# MSS_CTRL_MSS_CTRL_50D00000h register map
Vendor: Texas Instruments
Peripheral module from a debugger description file (folder AM261x).
Registers are 32-bit, read-write, reset values left out (the file's numbers can be read two ways) unless marked. A register's access mark holds for its fields unless they carry their own. Offsets are as the file gives them; lines under a group give offsets from that group; [hi:lo] are bit positions; {n}, {i} and the like mark numbered series; 'fields as' and 'values as' point back to an identical list; <NAME> marks a mode.

## MSS_CTRL (part 1 of 4)
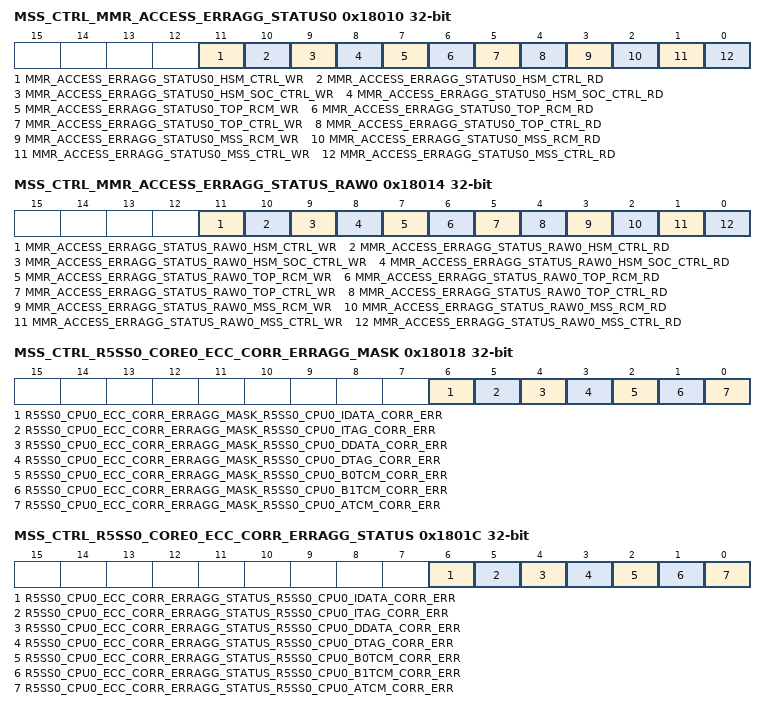
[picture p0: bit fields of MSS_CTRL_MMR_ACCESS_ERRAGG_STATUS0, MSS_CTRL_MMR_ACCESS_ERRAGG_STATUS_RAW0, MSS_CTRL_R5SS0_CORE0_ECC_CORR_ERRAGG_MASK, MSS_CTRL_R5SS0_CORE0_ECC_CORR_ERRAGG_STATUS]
0x18010 MSS_CTRL_MMR_ACCESS_ERRAGG_STATUS0 access not given — This register shows the Status of Unmasked MMR Access Errors.
  [11] MMR_ACCESS_ERRAGG_STATUS0_HSM_CTRL_WR — Status of Interrupt from HSM_CTRLSet only if Interupt is unmasked in MMR_ACCESS_ERRAGG_MASK0Wrie 0x1 to clear this interrupt. (access R/W1TC)
  [10] MMR_ACCESS_ERRAGG_STATUS0_HSM_CTRL_RD — Status of Interrupt from HSM_CTRLSet only if Interupt is unmasked in MMR_ACCESS_ERRAGG_MASK0Wrie 0x1 to clear this interrupt. (access R/W1TC)
  [9] MMR_ACCESS_ERRAGG_STATUS0_HSM_SOC_CTRL_WR — Status of Interrupt from HSM_SOC_CTRLSet only if Interupt is unmasked in MMR_ACCESS_ERRAGG_MASK0Wrie 0x1 to clear this interrupt. (access R/W1TC)
  [8] MMR_ACCESS_ERRAGG_STATUS0_HSM_SOC_CTRL_RD — Status of Interrupt from HSM_SOC_CTRLSet only if Interupt is unmasked in MMR_ACCESS_ERRAGG_MASK0Wrie 0x1 to clear this interrupt. (access R/W1TC)
  [7] MMR_ACCESS_ERRAGG_STATUS0_TOP_RCM_WR — Status of Interrupt from TOP_RCMSet only if Interupt is unmasked in MMR_ACCESS_ERRAGG_MASK0Wrie 0x1 to clear this interrupt. (access R/W1TC)
  [6] MMR_ACCESS_ERRAGG_STATUS0_TOP_RCM_RD — Status of Interrupt from TOP_RCMSet only if Interupt is unmasked in MMR_ACCESS_ERRAGG_MASK0Wrie 0x1 to clear this interrupt. (access R/W1TC)
  [5] MMR_ACCESS_ERRAGG_STATUS0_TOP_CTRL_WR — Status of Interrupt from TOP_CTRLSet only if Interupt is unmasked in MMR_ACCESS_ERRAGG_MASK0Wrie 0x1 to clear this interrupt. (access R/W1TC)
  [4] MMR_ACCESS_ERRAGG_STATUS0_TOP_CTRL_RD — Status of Interrupt from TOP_CTRLSet only if Interupt is unmasked in MMR_ACCESS_ERRAGG_MASK0Wrie 0x1 to clear this interrupt. (access R/W1TC)
  [3] MMR_ACCESS_ERRAGG_STATUS0_MSS_RCM_WR — Status of Interrupt from MSS_RCMSet only if Interupt is unmasked in MMR_ACCESS_ERRAGG_MASK0Wrie 0x1 to clear this interrupt. (access R/W1TC)
  [2] MMR_ACCESS_ERRAGG_STATUS0_MSS_RCM_RD — Status of Interrupt from MSS_RCMSet only if Interupt is unmasked in MMR_ACCESS_ERRAGG_MASK0Wrie 0x1 to clear this interrupt. (access R/W1TC)
  [1] MMR_ACCESS_ERRAGG_STATUS0_MSS_CTRL_WR — Status of Interrupt from MSS_CTRLSet only if Interupt is unmasked in MMR_ACCESS_ERRAGG_MASK0Wrie 0x1 to clear this interrupt. (access R/W1TC)
  [0] MMR_ACCESS_ERRAGG_STATUS0_MSS_CTRL_RD — Status of Interrupt from MSS_CTRLSet only if Interupt is unmasked in MMR_ACCESS_ERRAGG_MASK0Wrie 0x1 to clear this interrupt. (access R/W1TC)
0x18014 MSS_CTRL_MMR_ACCESS_ERRAGG_STATUS_RAW0 access not given — This register shows the Status of all MMR Access Errors.
  [11] MMR_ACCESS_ERRAGG_STATUS_RAW0_HSM_CTRL_WR — Raw Status of Interrupt from HSM_CTRL. Set irrespective if the Interupt is masked or unmasked in MMR_ACCESS_ERRAGG_MASK0 (access R/W1TC)
  [10] MMR_ACCESS_ERRAGG_STATUS_RAW0_HSM_CTRL_RD — Raw Status of Interrupt from HSM_CTRL. Set irrespective if the Interupt is masked or unmasked in MMR_ACCESS_ERRAGG_MASK0 (access R/W1TC)
  [9] MMR_ACCESS_ERRAGG_STATUS_RAW0_HSM_SOC_CTRL_WR — Raw Status of Interrupt from HSM_SOC_CTRL. Set irrespective if the Interupt is masked or unmasked in MMR_ACCESS_ERRAGG_MASK0 (access R/W1TC)
  [8] MMR_ACCESS_ERRAGG_STATUS_RAW0_HSM_SOC_CTRL_RD — Raw Status of Interrupt from HSM_SOC_CTRL. Set irrespective if the Interupt is masked or unmasked in MMR_ACCESS_ERRAGG_MASK0 (access R/W1TC)
  [7] MMR_ACCESS_ERRAGG_STATUS_RAW0_TOP_RCM_WR — Raw Status of Interrupt from TOP_RCM. Set irrespective if the Interupt is masked or unmasked in MMR_ACCESS_ERRAGG_MASK0 (access R/W1TC)
  [6] MMR_ACCESS_ERRAGG_STATUS_RAW0_TOP_RCM_RD — Raw Status of Interrupt from TOP_RCM. Set irrespective if the Interupt is masked or unmasked in MMR_ACCESS_ERRAGG_MASK0 (access R/W1TC)
  [5] MMR_ACCESS_ERRAGG_STATUS_RAW0_TOP_CTRL_WR — Raw Status of Interrupt from TOP_CTRL. Set irrespective if the Interupt is masked or unmasked in MMR_ACCESS_ERRAGG_MASK0 (access R/W1TC)
  [4] MMR_ACCESS_ERRAGG_STATUS_RAW0_TOP_CTRL_RD — Raw Status of Interrupt from TOP_CTRL. Set irrespective if the Interupt is masked or unmasked in MMR_ACCESS_ERRAGG_MASK0 (access R/W1TC)
  [3] MMR_ACCESS_ERRAGG_STATUS_RAW0_MSS_RCM_WR — Raw Status of Interrupt from MSS_RCM. Set irrespective if the Interupt is masked or unmasked in MMR_ACCESS_ERRAGG_MASK0 (access R/W1TC)
  [2] MMR_ACCESS_ERRAGG_STATUS_RAW0_MSS_RCM_RD — Raw Status of Interrupt from MSS_RCM. Set irrespective if the Interupt is masked or unmasked in MMR_ACCESS_ERRAGG_MASK0 (access R/W1TC)
  [1] MMR_ACCESS_ERRAGG_STATUS_RAW0_MSS_CTRL_WR — Raw Status of Interrupt from MSS_CTRL. Set irrespective if the Interupt is masked or unmasked in MMR_ACCESS_ERRAGG_MASK0 (access R/W1TC)
  [0] MMR_ACCESS_ERRAGG_STATUS_RAW0_MSS_CTRL_RD — Raw Status of Interrupt from MSS_CTRL. Set irrespective if the Interupt is masked or unmasked in MMR_ACCESS_ERRAGG_MASK0 (access R/W1TC)
0x18018 MSS_CTRL_R5SS0_CORE0_ECC_CORR_ERRAGG_MASK — Register to Mask Correctable error from R5SS0 CORE0 Memories.
  [6] R5SS0_CPU0_ECC_CORR_ERRAGG_MASK_R5SS0_CPU0_IDATA_CORR_ERR — Mask Interrupt for correctable errors to aggregated Interrupt of corresponding CPU1 : Interrupt is Masked0 : Interrupt is Unmasked
  [5] R5SS0_CPU0_ECC_CORR_ERRAGG_MASK_R5SS0_CPU0_ITAG_CORR_ERR — Mask Interrupt for correctable errors to aggregated Interrupt of corresponding CPU1 : Interrupt is Masked0 : Interrupt is Unmasked
  [4] R5SS0_CPU0_ECC_CORR_ERRAGG_MASK_R5SS0_CPU0_DDATA_CORR_ERR — Mask Interrupt for correctable errors to aggregated Interrupt of corresponding CPU1 : Interrupt is Masked0 : Interrupt is Unmasked
  [3] R5SS0_CPU0_ECC_CORR_ERRAGG_MASK_R5SS0_CPU0_DTAG_CORR_ERR — Mask Interrupt for correctable errors to aggregated Interrupt of corresponding CPU1 : Interrupt is Masked0 : Interrupt is Unmasked
  [2] R5SS0_CPU0_ECC_CORR_ERRAGG_MASK_R5SS0_CPU0_B0TCM_CORR_ERR — Mask Interrupt for correctable errors to aggregated Interrupt of corresponding CPU1 : Interrupt is Masked0 : Interrupt is Unmasked
  [1] R5SS0_CPU0_ECC_CORR_ERRAGG_MASK_R5SS0_CPU0_B1TCM_CORR_ERR — Mask Interrupt for correctable errors to aggregated Interrupt of corresponding CPU1 : Interrupt is Masked0 : Interrupt is Unmasked
  [0] R5SS0_CPU0_ECC_CORR_ERRAGG_MASK_R5SS0_CPU0_ATCM_CORR_ERR — Mask Interrupt for correctable errors to aggregated Interrupt of corresponding CPU1 : Interrupt is Masked0 : Interrupt is Unmasked
0x1801C MSS_CTRL_R5SS0_CORE0_ECC_CORR_ERRAGG_STATUS access not given — Status register based on mask for correctable error R5SS0 CORE0 Memories.
  [6] R5SS0_CPU0_ECC_CORR_ERRAGG_STATUS_R5SS0_CPU0_IDATA_CORR_ERR — Status of Interrupt from correctable error of corresponding CPUSet only if Interupt is unmasked in corresponding R5SS*_CPU*_ECC_CORR_ERRAGG_MASK registerWrie 0x1 to clear this interrupt. (access R/W1TC)
  [5] R5SS0_CPU0_ECC_CORR_ERRAGG_STATUS_R5SS0_CPU0_ITAG_CORR_ERR — Status of Interrupt from correctable error of corresponding CPUSet only if Interupt is unmasked in corresponding R5SS*_CPU*_ECC_CORR_ERRAGG_MASK registerWrie 0x1 to clear this interrupt. (access R/W1TC)
  [4] R5SS0_CPU0_ECC_CORR_ERRAGG_STATUS_R5SS0_CPU0_DDATA_CORR_ERR — Status of Interrupt from correctable error of corresponding CPUSet only if Interupt is unmasked in corresponding R5SS*_CPU*_ECC_CORR_ERRAGG_MASK registerWrie 0x1 to clear this interrupt. (access R/W1TC)
  [3] R5SS0_CPU0_ECC_CORR_ERRAGG_STATUS_R5SS0_CPU0_DTAG_CORR_ERR — Status of Interrupt from correctable error of corresponding CPUSet only if Interupt is unmasked in corresponding R5SS*_CPU*_ECC_CORR_ERRAGG_MASK registerWrie 0x1 to clear this interrupt. (access R/W1TC)
  [2] R5SS0_CPU0_ECC_CORR_ERRAGG_STATUS_R5SS0_CPU0_B0TCM_CORR_ERR — Status of Interrupt from correctable error of corresponding CPUSet only if Interupt is unmasked in corresponding R5SS*_CPU*_ECC_CORR_ERRAGG_MASK registerWrie 0x1 to clear this interrupt. (access R/W1TC)
  [1] R5SS0_CPU0_ECC_CORR_ERRAGG_STATUS_R5SS0_CPU0_B1TCM_CORR_ERR — Status of Interrupt from correctable error of corresponding CPUSet only if Interupt is unmasked in corresponding R5SS*_CPU*_ECC_CORR_ERRAGG_MASK registerWrie 0x1 to clear this interrupt. (access R/W1TC)
  [0] R5SS0_CPU0_ECC_CORR_ERRAGG_STATUS_R5SS0_CPU0_ATCM_CORR_ERR — Status of Interrupt from correctable error of corresponding CPUSet only if Interupt is unmasked in corresponding R5SS*_CPU*_ECC_CORR_ERRAGG_MASK registerWrie 0x1 to clear this interrupt. (access R/W1TC)
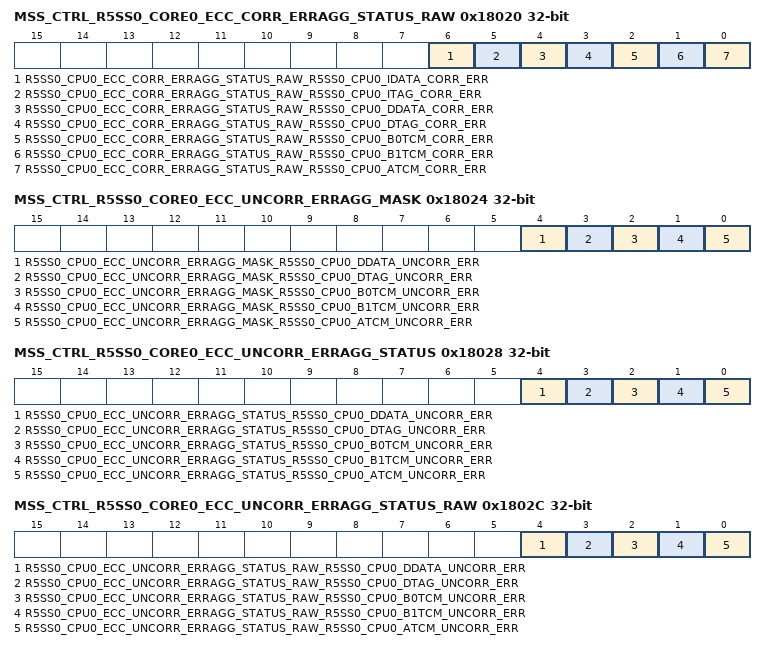
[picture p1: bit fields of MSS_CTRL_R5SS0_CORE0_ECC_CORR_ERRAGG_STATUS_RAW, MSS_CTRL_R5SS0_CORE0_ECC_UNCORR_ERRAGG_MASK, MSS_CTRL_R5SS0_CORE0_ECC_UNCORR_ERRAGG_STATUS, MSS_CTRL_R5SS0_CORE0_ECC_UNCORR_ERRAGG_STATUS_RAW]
0x18020 MSS_CTRL_R5SS0_CORE0_ECC_CORR_ERRAGG_STATUS_RAW access not given — Raw status for correctable error from R5SS0 CORE0 Memories.
  [6] R5SS0_CPU0_ECC_CORR_ERRAGG_STATUS_RAW_R5SS0_CPU0_IDATA_CORR_ERR — Raw Status of Interrupt from correctable error of corresponding CPUSet only if Interupt is unmasked in corresponding R5SS*_CPU*_ECC_CORR_ERRAGG_MASK registerWrie 0x1 to clear this interrupt. (access R/W1TC)
  [5] R5SS0_CPU0_ECC_CORR_ERRAGG_STATUS_RAW_R5SS0_CPU0_ITAG_CORR_ERR — Raw Status of Interrupt from correctable error of corresponding CPUSet only if Interupt is unmasked in corresponding R5SS*_CPU*_ECC_CORR_ERRAGG_MASK registerWrie 0x1 to clear this interrupt. (access R/W1TC)
  [4] R5SS0_CPU0_ECC_CORR_ERRAGG_STATUS_RAW_R5SS0_CPU0_DDATA_CORR_ERR — Raw Status of Interrupt from correctable error of corresponding CPUSet only if Interupt is unmasked in corresponding R5SS*_CPU*_ECC_CORR_ERRAGG_MASK registerWrie 0x1 to clear this interrupt. (access R/W1TC)
  [3] R5SS0_CPU0_ECC_CORR_ERRAGG_STATUS_RAW_R5SS0_CPU0_DTAG_CORR_ERR — Raw Status of Interrupt from correctable error of corresponding CPUSet only if Interupt is unmasked in corresponding R5SS*_CPU*_ECC_CORR_ERRAGG_MASK registerWrie 0x1 to clear this interrupt. (access R/W1TC)
  [2] R5SS0_CPU0_ECC_CORR_ERRAGG_STATUS_RAW_R5SS0_CPU0_B0TCM_CORR_ERR — Raw Status of Interrupt from correctable error of corresponding CPUSet only if Interupt is unmasked in corresponding R5SS*_CPU*_ECC_CORR_ERRAGG_MASK registerWrie 0x1 to clear this interrupt. (access R/W1TC)
  [1] R5SS0_CPU0_ECC_CORR_ERRAGG_STATUS_RAW_R5SS0_CPU0_B1TCM_CORR_ERR — Raw Status of Interrupt from correctable error of corresponding CPUSet only if Interupt is unmasked in corresponding R5SS*_CPU*_ECC_CORR_ERRAGG_MASK registerWrie 0x1 to clear this interrupt. (access R/W1TC)
  [0] R5SS0_CPU0_ECC_CORR_ERRAGG_STATUS_RAW_R5SS0_CPU0_ATCM_CORR_ERR — Raw Status of Interrupt from correctable error of corresponding CPUSet only if Interupt is unmasked in corresponding R5SS*_CPU*_ECC_CORR_ERRAGG_MASK registerWrie 0x1 to clear this interrupt. (access R/W1TC)
0x18024 MSS_CTRL_R5SS0_CORE0_ECC_UNCORR_ERRAGG_MASK — Register to Mask Uncorrectable error from R5SS0 CORE0 Memories.
  [4] R5SS0_CPU0_ECC_UNCORR_ERRAGG_MASK_R5SS0_CPU0_DDATA_UNCORR_ERR — Mask Interrupt for correctable errors to aggregated Interrupt of corresponding CPU1 : Interrupt is Masked0 : Interrupt is Unmasked
  [3] R5SS0_CPU0_ECC_UNCORR_ERRAGG_MASK_R5SS0_CPU0_DTAG_UNCORR_ERR — Mask Interrupt for correctable errors to aggregated Interrupt of corresponding CPU1 : Interrupt is Masked0 : Interrupt is Unmasked
  [2] R5SS0_CPU0_ECC_UNCORR_ERRAGG_MASK_R5SS0_CPU0_B0TCM_UNCORR_ERR — Mask Interrupt for correctable errors to aggregated Interrupt of corresponding CPU1 : Interrupt is Masked0 : Interrupt is Unmasked
  [1] R5SS0_CPU0_ECC_UNCORR_ERRAGG_MASK_R5SS0_CPU0_B1TCM_UNCORR_ERR — Mask Interrupt for correctable errors to aggregated Interrupt of corresponding CPU1 : Interrupt is Masked0 : Interrupt is Unmasked
  [0] R5SS0_CPU0_ECC_UNCORR_ERRAGG_MASK_R5SS0_CPU0_ATCM_UNCORR_ERR — Mask Interrupt for correctable errors to aggregated Interrupt of corresponding CPU1 : Interrupt is Masked0 : Interrupt is Unmasked
0x18028 MSS_CTRL_R5SS0_CORE0_ECC_UNCORR_ERRAGG_STATUS access not given — Status register based on mask for uncorrectable error R5SS0 CORE0 Memories.
  [4] R5SS0_CPU0_ECC_UNCORR_ERRAGG_STATUS_R5SS0_CPU0_DDATA_UNCORR_ERR — Status of Interrupt from correctable error of corresponding CPUSet only if Interupt is unmasked in corresponding R5SS*_CPU*_ECC_UNCORR_ERRAGG_MASK registerWrie 0x1 to clear this interrupt. (access R/W1TC)
  [3] R5SS0_CPU0_ECC_UNCORR_ERRAGG_STATUS_R5SS0_CPU0_DTAG_UNCORR_ERR — Status of Interrupt from correctable error of corresponding CPUSet only if Interupt is unmasked in corresponding R5SS*_CPU*_ECC_UNCORR_ERRAGG_MASK registerWrie 0x1 to clear this interrupt. (access R/W1TC)
  [2] R5SS0_CPU0_ECC_UNCORR_ERRAGG_STATUS_R5SS0_CPU0_B0TCM_UNCORR_ERR — Status of Interrupt from correctable error of corresponding CPUSet only if Interupt is unmasked in corresponding R5SS*_CPU*_ECC_UNCORR_ERRAGG_MASK registerWrie 0x1 to clear this interrupt. (access R/W1TC)
  [1] R5SS0_CPU0_ECC_UNCORR_ERRAGG_STATUS_R5SS0_CPU0_B1TCM_UNCORR_ERR — Status of Interrupt from correctable error of corresponding CPUSet only if Interupt is unmasked in corresponding R5SS*_CPU*_ECC_UNCORR_ERRAGG_MASK registerWrie 0x1 to clear this interrupt. (access R/W1TC)
  [0] R5SS0_CPU0_ECC_UNCORR_ERRAGG_STATUS_R5SS0_CPU0_ATCM_UNCORR_ERR — Status of Interrupt from correctable error of corresponding CPUSet only if Interupt is unmasked in corresponding R5SS*_CPU*_ECC_UNCORR_ERRAGG_MASK registerWrie 0x1 to clear this interrupt. (access R/W1TC)
0x1802C MSS_CTRL_R5SS0_CORE0_ECC_UNCORR_ERRAGG_STATUS_RAW access not given — Raw status for uncorrectable error from R5SS0 CORE0 Memories.
  [4] R5SS0_CPU0_ECC_UNCORR_ERRAGG_STATUS_RAW_R5SS0_CPU0_DDATA_UNCORR_ERR — Raw Status of Interrupt from correctable error of corresponding CPUSet only if Interupt is unmasked in corresponding R5SS*_CPU*_ECC_UNCORR_ERRAGG_MASK registerWrie 0x1 to clear this interrupt. (access R/W1TC)
  [3] R5SS0_CPU0_ECC_UNCORR_ERRAGG_STATUS_RAW_R5SS0_CPU0_DTAG_UNCORR_ERR — Raw Status of Interrupt from correctable error of corresponding CPUSet only if Interupt is unmasked in corresponding R5SS*_CPU*_ECC_UNCORR_ERRAGG_MASK registerWrie 0x1 to clear this interrupt. (access R/W1TC)
  [2] R5SS0_CPU0_ECC_UNCORR_ERRAGG_STATUS_RAW_R5SS0_CPU0_B0TCM_UNCORR_ERR — Raw Status of Interrupt from correctable error of corresponding CPUSet only if Interupt is unmasked in corresponding R5SS*_CPU*_ECC_UNCORR_ERRAGG_MASK registerWrie 0x1 to clear this interrupt. (access R/W1TC)
  [1] R5SS0_CPU0_ECC_UNCORR_ERRAGG_STATUS_RAW_R5SS0_CPU0_B1TCM_UNCORR_ERR — Raw Status of Interrupt from correctable error of corresponding CPUSet only if Interupt is unmasked in corresponding R5SS*_CPU*_ECC_UNCORR_ERRAGG_MASK registerWrie 0x1 to clear this interrupt. (access R/W1TC)
  [0] R5SS0_CPU0_ECC_UNCORR_ERRAGG_STATUS_RAW_R5SS0_CPU0_ATCM_UNCORR_ERR — Raw Status of Interrupt from correctable error of corresponding CPUSet only if Interupt is unmasked in corresponding R5SS*_CPU*_ECC_UNCORR_ERRAGG_MASK registerWrie 0x1 to clear this interrupt. (access R/W1TC)
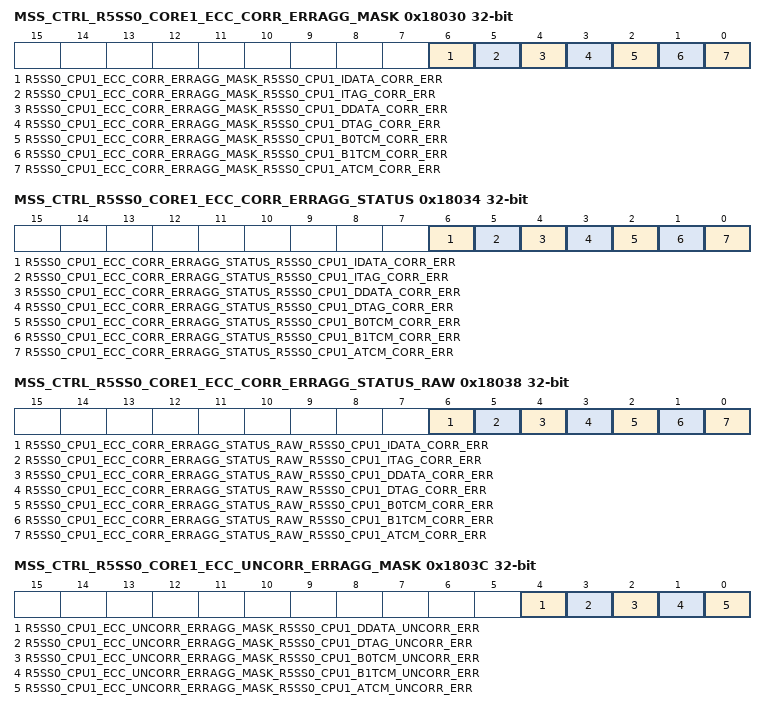
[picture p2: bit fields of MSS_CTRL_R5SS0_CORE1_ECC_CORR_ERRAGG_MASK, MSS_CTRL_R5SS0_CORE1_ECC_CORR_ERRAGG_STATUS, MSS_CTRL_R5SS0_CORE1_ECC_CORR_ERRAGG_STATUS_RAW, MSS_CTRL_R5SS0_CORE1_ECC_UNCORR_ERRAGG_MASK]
0x18030 MSS_CTRL_R5SS0_CORE1_ECC_CORR_ERRAGG_MASK — Register to Mask Correctable error from R5SS0 CORE1 Memories.
  [6] R5SS0_CPU1_ECC_CORR_ERRAGG_MASK_R5SS0_CPU1_IDATA_CORR_ERR — Mask Interrupt for correctable errors to aggregated Interrupt of corresponding CPU1 : Interrupt is Masked0 : Interrupt is Unmasked
  [5] R5SS0_CPU1_ECC_CORR_ERRAGG_MASK_R5SS0_CPU1_ITAG_CORR_ERR — Mask Interrupt for correctable errors to aggregated Interrupt of corresponding CPU1 : Interrupt is Masked0 : Interrupt is Unmasked
  [4] R5SS0_CPU1_ECC_CORR_ERRAGG_MASK_R5SS0_CPU1_DDATA_CORR_ERR — Mask Interrupt for correctable errors to aggregated Interrupt of corresponding CPU1 : Interrupt is Masked0 : Interrupt is Unmasked
  [3] R5SS0_CPU1_ECC_CORR_ERRAGG_MASK_R5SS0_CPU1_DTAG_CORR_ERR — Mask Interrupt for correctable errors to aggregated Interrupt of corresponding CPU1 : Interrupt is Masked0 : Interrupt is Unmasked
  [2] R5SS0_CPU1_ECC_CORR_ERRAGG_MASK_R5SS0_CPU1_B0TCM_CORR_ERR — Mask Interrupt for correctable errors to aggregated Interrupt of corresponding CPU1 : Interrupt is Masked0 : Interrupt is Unmasked
  [1] R5SS0_CPU1_ECC_CORR_ERRAGG_MASK_R5SS0_CPU1_B1TCM_CORR_ERR — Mask Interrupt for correctable errors to aggregated Interrupt of corresponding CPU1 : Interrupt is Masked0 : Interrupt is Unmasked
  [0] R5SS0_CPU1_ECC_CORR_ERRAGG_MASK_R5SS0_CPU1_ATCM_CORR_ERR — Mask Interrupt for correctable errors to aggregated Interrupt of corresponding CPU1 : Interrupt is Masked0 : Interrupt is Unmasked
0x18034 MSS_CTRL_R5SS0_CORE1_ECC_CORR_ERRAGG_STATUS access not given — Status register based on mask for correctable error R5SS0 CORE1 Memories.
  [6] R5SS0_CPU1_ECC_CORR_ERRAGG_STATUS_R5SS0_CPU1_IDATA_CORR_ERR — Status of Interrupt from correctable error of corresponding CPUSet only if Interupt is unmasked in corresponding R5SS*_CPU*_ECC_CORR_ERRAGG_MASK registerWrie 0x1 to clear this interrupt. (access R/W1TC)
  [5] R5SS0_CPU1_ECC_CORR_ERRAGG_STATUS_R5SS0_CPU1_ITAG_CORR_ERR — Status of Interrupt from correctable error of corresponding CPUSet only if Interupt is unmasked in corresponding R5SS*_CPU*_ECC_CORR_ERRAGG_MASK registerWrie 0x1 to clear this interrupt. (access R/W1TC)
  [4] R5SS0_CPU1_ECC_CORR_ERRAGG_STATUS_R5SS0_CPU1_DDATA_CORR_ERR — Status of Interrupt from correctable error of corresponding CPUSet only if Interupt is unmasked in corresponding R5SS*_CPU*_ECC_CORR_ERRAGG_MASK registerWrie 0x1 to clear this interrupt. (access R/W1TC)
  [3] R5SS0_CPU1_ECC_CORR_ERRAGG_STATUS_R5SS0_CPU1_DTAG_CORR_ERR — Status of Interrupt from correctable error of corresponding CPUSet only if Interupt is unmasked in corresponding R5SS*_CPU*_ECC_CORR_ERRAGG_MASK registerWrie 0x1 to clear this interrupt. (access R/W1TC)
  [2] R5SS0_CPU1_ECC_CORR_ERRAGG_STATUS_R5SS0_CPU1_B0TCM_CORR_ERR — Status of Interrupt from correctable error of corresponding CPUSet only if Interupt is unmasked in corresponding R5SS*_CPU*_ECC_CORR_ERRAGG_MASK registerWrie 0x1 to clear this interrupt. (access R/W1TC)
  [1] R5SS0_CPU1_ECC_CORR_ERRAGG_STATUS_R5SS0_CPU1_B1TCM_CORR_ERR — Status of Interrupt from correctable error of corresponding CPUSet only if Interupt is unmasked in corresponding R5SS*_CPU*_ECC_CORR_ERRAGG_MASK registerWrie 0x1 to clear this interrupt. (access R/W1TC)
  [0] R5SS0_CPU1_ECC_CORR_ERRAGG_STATUS_R5SS0_CPU1_ATCM_CORR_ERR — Status of Interrupt from correctable error of corresponding CPUSet only if Interupt is unmasked in corresponding R5SS*_CPU*_ECC_CORR_ERRAGG_MASK registerWrie 0x1 to clear this interrupt. (access R/W1TC)
0x18038 MSS_CTRL_R5SS0_CORE1_ECC_CORR_ERRAGG_STATUS_RAW access not given — Raw status for correctable error from R5SS0 CORE1 Memories.
  [6] R5SS0_CPU1_ECC_CORR_ERRAGG_STATUS_RAW_R5SS0_CPU1_IDATA_CORR_ERR — Raw Status of Interrupt from correctable error of corresponding CPUSet only if Interupt is unmasked in corresponding R5SS*_CPU*_ECC_CORR_ERRAGG_MASK registerWrie 0x1 to clear this interrupt. (access R/W1TC)
  [5] R5SS0_CPU1_ECC_CORR_ERRAGG_STATUS_RAW_R5SS0_CPU1_ITAG_CORR_ERR — Raw Status of Interrupt from correctable error of corresponding CPUSet only if Interupt is unmasked in corresponding R5SS*_CPU*_ECC_CORR_ERRAGG_MASK registerWrie 0x1 to clear this interrupt. (access R/W1TC)
  [4] R5SS0_CPU1_ECC_CORR_ERRAGG_STATUS_RAW_R5SS0_CPU1_DDATA_CORR_ERR — Raw Status of Interrupt from correctable error of corresponding CPUSet only if Interupt is unmasked in corresponding R5SS*_CPU*_ECC_CORR_ERRAGG_MASK registerWrie 0x1 to clear this interrupt. (access R/W1TC)
  [3] R5SS0_CPU1_ECC_CORR_ERRAGG_STATUS_RAW_R5SS0_CPU1_DTAG_CORR_ERR — Raw Status of Interrupt from correctable error of corresponding CPUSet only if Interupt is unmasked in corresponding R5SS*_CPU*_ECC_CORR_ERRAGG_MASK registerWrie 0x1 to clear this interrupt. (access R/W1TC)
  [2] R5SS0_CPU1_ECC_CORR_ERRAGG_STATUS_RAW_R5SS0_CPU1_B0TCM_CORR_ERR — Raw Status of Interrupt from correctable error of corresponding CPUSet only if Interupt is unmasked in corresponding R5SS*_CPU*_ECC_CORR_ERRAGG_MASK registerWrie 0x1 to clear this interrupt. (access R/W1TC)
  [1] R5SS0_CPU1_ECC_CORR_ERRAGG_STATUS_RAW_R5SS0_CPU1_B1TCM_CORR_ERR — Raw Status of Interrupt from correctable error of corresponding CPUSet only if Interupt is unmasked in corresponding R5SS*_CPU*_ECC_CORR_ERRAGG_MASK registerWrie 0x1 to clear this interrupt. (access R/W1TC)
  [0] R5SS0_CPU1_ECC_CORR_ERRAGG_STATUS_RAW_R5SS0_CPU1_ATCM_CORR_ERR — Raw Status of Interrupt from correctable error of corresponding CPUSet only if Interupt is unmasked in corresponding R5SS*_CPU*_ECC_CORR_ERRAGG_MASK registerWrie 0x1 to clear this interrupt. (access R/W1TC)
0x1803C MSS_CTRL_R5SS0_CORE1_ECC_UNCORR_ERRAGG_MASK — Register to Mask Uncorrectable error from R5SS0 CORE1 Memories.
  [4] R5SS0_CPU1_ECC_UNCORR_ERRAGG_MASK_R5SS0_CPU1_DDATA_UNCORR_ERR — Mask Interrupt for correctable errors to aggregated Interrupt of corresponding CPU1 : Interrupt is Masked0 : Interrupt is Unmasked
  [3] R5SS0_CPU1_ECC_UNCORR_ERRAGG_MASK_R5SS0_CPU1_DTAG_UNCORR_ERR — Mask Interrupt for correctable errors to aggregated Interrupt of corresponding CPU1 : Interrupt is Masked0 : Interrupt is Unmasked
  [2] R5SS0_CPU1_ECC_UNCORR_ERRAGG_MASK_R5SS0_CPU1_B0TCM_UNCORR_ERR — Mask Interrupt for correctable errors to aggregated Interrupt of corresponding CPU1 : Interrupt is Masked0 : Interrupt is Unmasked
  [1] R5SS0_CPU1_ECC_UNCORR_ERRAGG_MASK_R5SS0_CPU1_B1TCM_UNCORR_ERR — Mask Interrupt for correctable errors to aggregated Interrupt of corresponding CPU1 : Interrupt is Masked0 : Interrupt is Unmasked
  [0] R5SS0_CPU1_ECC_UNCORR_ERRAGG_MASK_R5SS0_CPU1_ATCM_UNCORR_ERR — Mask Interrupt for correctable errors to aggregated Interrupt of corresponding CPU1 : Interrupt is Masked0 : Interrupt is Unmasked
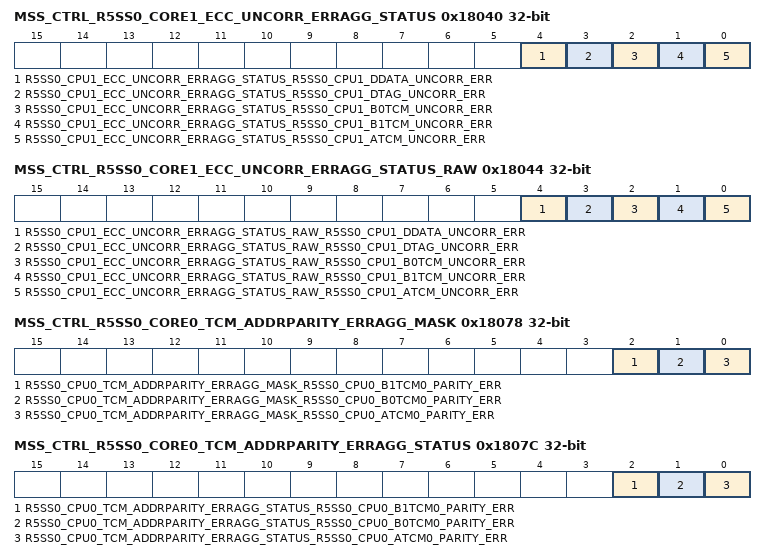
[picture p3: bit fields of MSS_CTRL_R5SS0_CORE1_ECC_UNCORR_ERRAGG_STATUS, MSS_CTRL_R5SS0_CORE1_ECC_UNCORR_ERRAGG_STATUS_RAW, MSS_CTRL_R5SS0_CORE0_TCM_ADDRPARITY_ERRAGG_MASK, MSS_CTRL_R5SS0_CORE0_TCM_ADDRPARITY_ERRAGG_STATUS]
0x18040 MSS_CTRL_R5SS0_CORE1_ECC_UNCORR_ERRAGG_STATUS access not given — Status register based on mask for uncorrectable error R5SS0 CORE1 Memories.
  [4] R5SS0_CPU1_ECC_UNCORR_ERRAGG_STATUS_R5SS0_CPU1_DDATA_UNCORR_ERR — Status of Interrupt from correctable error of corresponding CPUSet only if Interupt is unmasked in corresponding R5SS*_CPU*_ECC_UNCORR_ERRAGG_MASK registerWrie 0x1 to clear this interrupt. (access R/W1TC)
  [3] R5SS0_CPU1_ECC_UNCORR_ERRAGG_STATUS_R5SS0_CPU1_DTAG_UNCORR_ERR — Status of Interrupt from correctable error of corresponding CPUSet only if Interupt is unmasked in corresponding R5SS*_CPU*_ECC_UNCORR_ERRAGG_MASK registerWrie 0x1 to clear this interrupt. (access R/W1TC)
  [2] R5SS0_CPU1_ECC_UNCORR_ERRAGG_STATUS_R5SS0_CPU1_B0TCM_UNCORR_ERR — Status of Interrupt from correctable error of corresponding CPUSet only if Interupt is unmasked in corresponding R5SS*_CPU*_ECC_UNCORR_ERRAGG_MASK registerWrie 0x1 to clear this interrupt. (access R/W1TC)
  [1] R5SS0_CPU1_ECC_UNCORR_ERRAGG_STATUS_R5SS0_CPU1_B1TCM_UNCORR_ERR — Status of Interrupt from correctable error of corresponding CPUSet only if Interupt is unmasked in corresponding R5SS*_CPU*_ECC_UNCORR_ERRAGG_MASK registerWrie 0x1 to clear this interrupt. (access R/W1TC)
  [0] R5SS0_CPU1_ECC_UNCORR_ERRAGG_STATUS_R5SS0_CPU1_ATCM_UNCORR_ERR — Status of Interrupt from correctable error of corresponding CPUSet only if Interupt is unmasked in corresponding R5SS*_CPU*_ECC_UNCORR_ERRAGG_MASK registerWrie 0x1 to clear this interrupt. (access R/W1TC)
0x18044 MSS_CTRL_R5SS0_CORE1_ECC_UNCORR_ERRAGG_STATUS_RAW access not given — Raw status for uncorrectable error from R5SS0 CORE1 Memories.
  [4] R5SS0_CPU1_ECC_UNCORR_ERRAGG_STATUS_RAW_R5SS0_CPU1_DDATA_UNCORR_ERR — Raw Status of Interrupt from correctable error of corresponding CPUSet only if Interupt is unmasked in corresponding R5SS*_CPU*_ECC_UNCORR_ERRAGG_MASK registerWrie 0x1 to clear this interrupt. (access R/W1TC)
  [3] R5SS0_CPU1_ECC_UNCORR_ERRAGG_STATUS_RAW_R5SS0_CPU1_DTAG_UNCORR_ERR — Raw Status of Interrupt from correctable error of corresponding CPUSet only if Interupt is unmasked in corresponding R5SS*_CPU*_ECC_UNCORR_ERRAGG_MASK registerWrie 0x1 to clear this interrupt. (access R/W1TC)
  [2] R5SS0_CPU1_ECC_UNCORR_ERRAGG_STATUS_RAW_R5SS0_CPU1_B0TCM_UNCORR_ERR — Raw Status of Interrupt from correctable error of corresponding CPUSet only if Interupt is unmasked in corresponding R5SS*_CPU*_ECC_UNCORR_ERRAGG_MASK registerWrie 0x1 to clear this interrupt. (access R/W1TC)
  [1] R5SS0_CPU1_ECC_UNCORR_ERRAGG_STATUS_RAW_R5SS0_CPU1_B1TCM_UNCORR_ERR — Raw Status of Interrupt from correctable error of corresponding CPUSet only if Interupt is unmasked in corresponding R5SS*_CPU*_ECC_UNCORR_ERRAGG_MASK registerWrie 0x1 to clear this interrupt. (access R/W1TC)
  [0] R5SS0_CPU1_ECC_UNCORR_ERRAGG_STATUS_RAW_R5SS0_CPU1_ATCM_UNCORR_ERR — Raw Status of Interrupt from correctable error of corresponding CPUSet only if Interupt is unmasked in corresponding R5SS*_CPU*_ECC_UNCORR_ERRAGG_MASK registerWrie 0x1 to clear this interrupt. (access R/W1TC)
0x18078 MSS_CTRL_R5SS0_CORE0_TCM_ADDRPARITY_ERRAGG_MASK — Register to Mask TCM address parity errors from R5SS0 CORE0.
  [2] R5SS0_CPU0_TCM_ADDRPARITY_ERRAGG_MASK_R5SS0_CPU0_B1TCM0_PARITY_ERR — Mask Interrupt for address parity error s to aggregated Interrupt of corresponding CPU1 : Interrupt is Masked0 : Interrupt is Unmasked
  [1] R5SS0_CPU0_TCM_ADDRPARITY_ERRAGG_MASK_R5SS0_CPU0_B0TCM0_PARITY_ERR — Mask Interrupt for address parity error s to aggregated Interrupt of corresponding CPU1 : Interrupt is Masked0 : Interrupt is Unmasked
  [0] R5SS0_CPU0_TCM_ADDRPARITY_ERRAGG_MASK_R5SS0_CPU0_ATCM0_PARITY_ERR — Mask Interrupt for address parity error s to aggregated Interrupt of corresponding CPU1 : Interrupt is Masked0 : Interrupt is Unmasked
0x1807C MSS_CTRL_R5SS0_CORE0_TCM_ADDRPARITY_ERRAGG_STATUS access not given — Status register based on mask for TCM address parity errors from R5SS0 CORE0.
  [2] R5SS0_CPU0_TCM_ADDRPARITY_ERRAGG_STATUS_R5SS0_CPU0_B1TCM0_PARITY_ERR — Status of Interrupt from address parity error of corresponding CPU*_TCM_ADDRPARITY_ERRAGG_MASK registerWrie 0x1 to clear this interrupt. (access R/W1TC)
  [1] R5SS0_CPU0_TCM_ADDRPARITY_ERRAGG_STATUS_R5SS0_CPU0_B0TCM0_PARITY_ERR — Status of Interrupt from address parity error of corresponding CPU*_TCM_ADDRPARITY_ERRAGG_MASK registerWrie 0x1 to clear this interrupt. (access R/W1TC)
  [0] R5SS0_CPU0_TCM_ADDRPARITY_ERRAGG_STATUS_R5SS0_CPU0_ATCM0_PARITY_ERR — Status of Interrupt from address parity error of corresponding CPU*_TCM_ADDRPARITY_ERRAGG_MASK registerWrie 0x1 to clear this interrupt. (access R/W1TC)
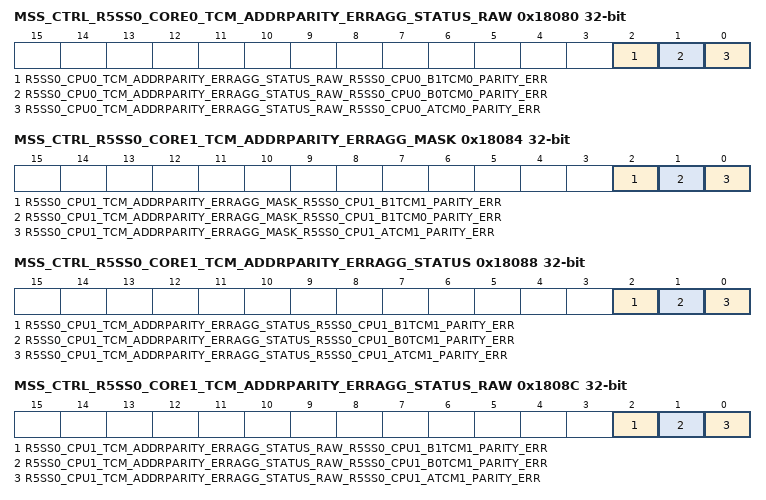
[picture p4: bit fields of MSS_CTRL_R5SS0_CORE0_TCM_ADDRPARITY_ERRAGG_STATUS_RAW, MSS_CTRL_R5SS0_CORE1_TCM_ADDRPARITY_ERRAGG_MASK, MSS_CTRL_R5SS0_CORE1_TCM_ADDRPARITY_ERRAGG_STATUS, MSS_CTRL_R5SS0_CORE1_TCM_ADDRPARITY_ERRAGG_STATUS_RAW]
0x18080 MSS_CTRL_R5SS0_CORE0_TCM_ADDRPARITY_ERRAGG_STATUS_RAW access not given — Raw status for TCM address parity errors from R5SS0 CORE0.
  [2] R5SS0_CPU0_TCM_ADDRPARITY_ERRAGG_STATUS_RAW_R5SS0_CPU0_B1TCM0_PARITY_ERR — Raw Status of Interrupt from address parity error of corresponding CPU*_TCM_ADDRPARITY_ERRAGG_MASK registerWrie 0x1 to clear this interrupt. (access R/W1TC)
  [1] R5SS0_CPU0_TCM_ADDRPARITY_ERRAGG_STATUS_RAW_R5SS0_CPU0_B0TCM0_PARITY_ERR — Raw Status of Interrupt from address parity error of corresponding CPU*_TCM_ADDRPARITY_ERRAGG_MASK registerWrie 0x1 to clear this interrupt. (access R/W1TC)
  [0] R5SS0_CPU0_TCM_ADDRPARITY_ERRAGG_STATUS_RAW_R5SS0_CPU0_ATCM0_PARITY_ERR — Raw Status of Interrupt from address parity error of corresponding CPU*_TCM_ADDRPARITY_ERRAGG_MASK registerWrie 0x1 to clear this interrupt. (access R/W1TC)
0x18084 MSS_CTRL_R5SS0_CORE1_TCM_ADDRPARITY_ERRAGG_MASK — Register to Mask TCM address parity errors from R5SS0 CORE1.
  [2] R5SS0_CPU1_TCM_ADDRPARITY_ERRAGG_MASK_R5SS0_CPU1_B1TCM1_PARITY_ERR — Mask Interrupt for address parity error s to aggregated Interrupt of corresponding CPU1 : Interrupt is Masked0 : Interrupt is Unmasked
  [1] R5SS0_CPU1_TCM_ADDRPARITY_ERRAGG_MASK_R5SS0_CPU1_B1TCM0_PARITY_ERR — Mask Interrupt for address parity error s to aggregated Interrupt of corresponding CPU1 : Interrupt is Masked0 : Interrupt is Unmasked
  [0] R5SS0_CPU1_TCM_ADDRPARITY_ERRAGG_MASK_R5SS0_CPU1_ATCM1_PARITY_ERR — Mask Interrupt for address parity error s to aggregated Interrupt of corresponding CPU1 : Interrupt is Masked0 : Interrupt is Unmasked
0x18088 MSS_CTRL_R5SS0_CORE1_TCM_ADDRPARITY_ERRAGG_STATUS access not given — Status register based on mask for TCM address parity errors from R5SS0 CORE1.
  [2] R5SS0_CPU1_TCM_ADDRPARITY_ERRAGG_STATUS_R5SS0_CPU1_B1TCM1_PARITY_ERR — Status of Interrupt from address parity error of corresponding CPU*_TCM_ADDRPARITY_ERRAGG_MASK registerWrie 0x1 to clear this interrupt. (access R/W1TC)
  [1] R5SS0_CPU1_TCM_ADDRPARITY_ERRAGG_STATUS_R5SS0_CPU1_B0TCM1_PARITY_ERR — Status of Interrupt from address parity error of corresponding CPU*_TCM_ADDRPARITY_ERRAGG_MASK registerWrie 0x1 to clear this interrupt. (access R/W1TC)
  [0] R5SS0_CPU1_TCM_ADDRPARITY_ERRAGG_STATUS_R5SS0_CPU1_ATCM1_PARITY_ERR — Status of Interrupt from address parity error of corresponding CPU*_TCM_ADDRPARITY_ERRAGG_MASK registerWrie 0x1 to clear this interrupt. (access R/W1TC)
0x1808C MSS_CTRL_R5SS0_CORE1_TCM_ADDRPARITY_ERRAGG_STATUS_RAW access not given — Raw status for TCM address parity errors from R5SS0 CORE1.
  [2] R5SS0_CPU1_TCM_ADDRPARITY_ERRAGG_STATUS_RAW_R5SS0_CPU1_B1TCM1_PARITY_ERR — Raw Status of Interrupt from address parity error of corresponding CPU*_TCM_ADDRPARITY_ERRAGG_MASK registerWrie 0x1 to clear this interrupt. (access R/W1TC)
  [1] R5SS0_CPU1_TCM_ADDRPARITY_ERRAGG_STATUS_RAW_R5SS0_CPU1_B0TCM1_PARITY_ERR — Raw Status of Interrupt from address parity error of corresponding CPU*_TCM_ADDRPARITY_ERRAGG_MASK registerWrie 0x1 to clear this interrupt. (access R/W1TC)
  [0] R5SS0_CPU1_TCM_ADDRPARITY_ERRAGG_STATUS_RAW_R5SS0_CPU1_ATCM1_PARITY_ERR — Raw Status of Interrupt from address parity error of corresponding CPU*_TCM_ADDRPARITY_ERRAGG_MASK registerWrie 0x1 to clear this interrupt. (access R/W1TC)
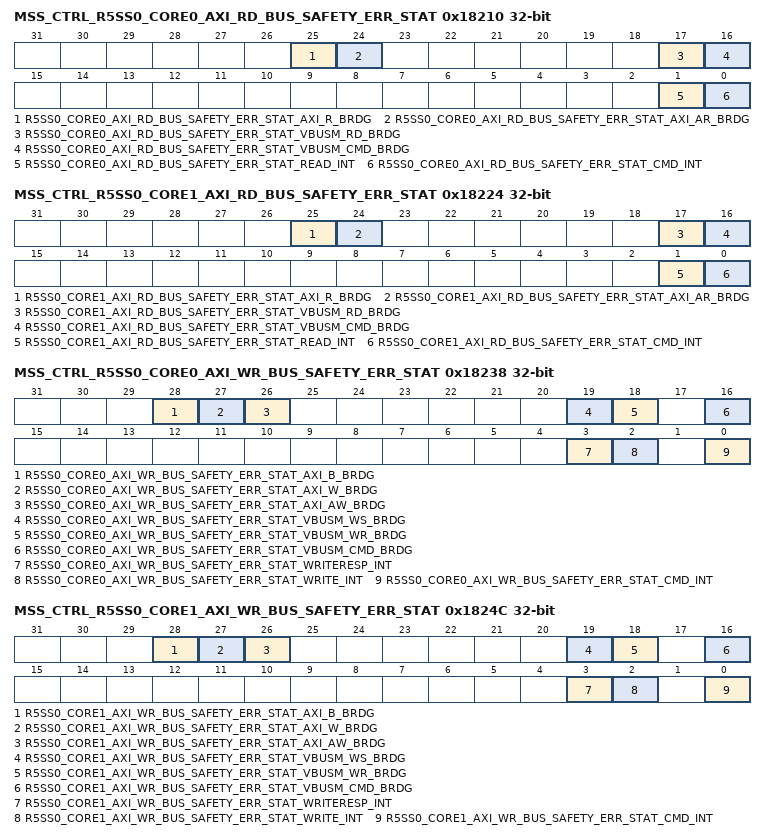
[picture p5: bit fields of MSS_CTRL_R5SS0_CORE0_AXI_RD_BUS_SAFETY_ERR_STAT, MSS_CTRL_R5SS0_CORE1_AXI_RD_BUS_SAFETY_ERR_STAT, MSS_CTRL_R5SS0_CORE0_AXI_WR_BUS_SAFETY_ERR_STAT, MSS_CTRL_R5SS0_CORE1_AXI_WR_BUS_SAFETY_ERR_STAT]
0x18210 MSS_CTRL_R5SS0_CORE0_AXI_RD_BUS_SAFETY_ERR_STAT ro — This register Indicates the Error Syndrome of Command errors in Bus Safety Comparator of R5SS0 CORE0 AXI RD Initiator Port.
  [25] R5SS0_CORE0_AXI_RD_BUS_SAFETY_ERR_STAT_AXI_R_BRDG — Read this bitfield for comapartor status for axi read data bus from R5SS at this port. 1'b1 on any of the bits indicates an error on Read bus.
  [24] R5SS0_CORE0_AXI_RD_BUS_SAFETY_ERR_STAT_AXI_AR_BRDG — Read this bitfield for comparator status for axi read command bus from R5SS for this port. 1'b1 on any of the bits indicates an error on Command Bus
  [17] R5SS0_CORE0_AXI_RD_BUS_SAFETY_ERR_STAT_VBUSM_RD_BRDG — Read this bitfield for comapartor status for vbusm read bus from R5SS at this port. 1'b1 on any of the bits indicates an error on Read bus.
  [16] R5SS0_CORE0_AXI_RD_BUS_SAFETY_ERR_STAT_VBUSM_CMD_BRDG — Read this bitfield for comparator status for vbusm command bus from R5SS for this port. 1'b1 on any of the bits indicates an error on Command Bus
  [1] R5SS0_CORE0_AXI_RD_BUS_SAFETY_ERR_STAT_READ_INT — Read this bitfield for comapartor status for read signals from interconnect at this port. 1'b1 on any of the bits indicates an error on Read bus.
  [0] R5SS0_CORE0_AXI_RD_BUS_SAFETY_ERR_STAT_CMD_INT — Read this bitfield for comparator status for command bus from interconnect for this port. 1'b1 on any of the bits indicates an error on Command Bus
0x18224 MSS_CTRL_R5SS0_CORE1_AXI_RD_BUS_SAFETY_ERR_STAT ro — This register Indicates the Error Syndrome of Command errors in Bus Safety Comparator of R5SS0 CORE1 AXI RD Initiator Port.
  [25] R5SS0_CORE1_AXI_RD_BUS_SAFETY_ERR_STAT_AXI_R_BRDG — Read this bitfield for comapartor status for axi read data bus from R5SS at this port. 1'b1 on any of the bits indicates an error on Read bus.
  [24] R5SS0_CORE1_AXI_RD_BUS_SAFETY_ERR_STAT_AXI_AR_BRDG — Read this bitfield for comparator status for axi read command bus from R5SS for this port. 1'b1 on any of the bits indicates an error on Command Bus
  [17] R5SS0_CORE1_AXI_RD_BUS_SAFETY_ERR_STAT_VBUSM_RD_BRDG — Read this bitfield for comapartor status for vbusm read bus from R5SS at this port. 1'b1 on any of the bits indicates an error on Read bus.
  [16] R5SS0_CORE1_AXI_RD_BUS_SAFETY_ERR_STAT_VBUSM_CMD_BRDG — Read this bitfield for comparator status for vbusm command bus from R5SS for this port. 1'b1 on any of the bits indicates an error on Command Bus
  [1] R5SS0_CORE1_AXI_RD_BUS_SAFETY_ERR_STAT_READ_INT — Read this bitfield for comapartor status for read signals at this port. 1'b1 on any of the bits indicates an error on Read bus.
  [0] R5SS0_CORE1_AXI_RD_BUS_SAFETY_ERR_STAT_CMD_INT — Read this bitfield for comparator status for command bus for this port. 1'b1 on any of the bits indicates an error on Command Bus
0x18238 MSS_CTRL_R5SS0_CORE0_AXI_WR_BUS_SAFETY_ERR_STAT ro — This register Indicates the Error Syndrome of Command errors in Bus Safety Comparator of R5SS0 CORE0 AXI WR Initiator Port.
  [28] R5SS0_CORE0_AXI_WR_BUS_SAFETY_ERR_STAT_AXI_B_BRDG — Read this bitfield for comapartor status for axi write response bus from R5SS at this port. 1'b1 on any of the bits indicates an error on Read bus.
  [27] R5SS0_CORE0_AXI_WR_BUS_SAFETY_ERR_STAT_AXI_W_BRDG — Read this bitfield for comparator status for axi write data bus from R5SS for this port. 1'b1 on any of the bits indicates an error on write Bus
  [26] R5SS0_CORE0_AXI_WR_BUS_SAFETY_ERR_STAT_AXI_AW_BRDG — Read this bitfield for comparator status for axi write command bus from R5SS for this port. 1'b1 on any of the bits indicates an error on write Bus
  [19] R5SS0_CORE0_AXI_WR_BUS_SAFETY_ERR_STAT_VBUSM_WS_BRDG — Read this bitfield for comparator status for vbusm write bus from R5SS for this port. 1'b1 on any of the bits indicates an error on Write Bus
  [18] R5SS0_CORE0_AXI_WR_BUS_SAFETY_ERR_STAT_VBUSM_WR_BRDG — Read this bitfield for comparator status for vbusm write bus from R5SS for this port. 1'b1 on any of the bits indicates an error on Write Bus
  [16] R5SS0_CORE0_AXI_WR_BUS_SAFETY_ERR_STAT_VBUSM_CMD_BRDG — Read this bitfield for comparator status for vbusm command bus from R5SS for this port. 1'b1 on any of the bits indicates an error on Command Bus
  [3] R5SS0_CORE0_AXI_WR_BUS_SAFETY_ERR_STAT_WRITERESP_INT — Read this bitfield for comparator status for Write response bus from interconnect for this port. 1'b1 indicates error on Write Response Bus.
  [2] R5SS0_CORE0_AXI_WR_BUS_SAFETY_ERR_STAT_WRITE_INT — Read this bitfield for comparator status for Write bus from interconnect for this port. 1'b1 at any bit indicates error on Write Bus
  [0] R5SS0_CORE0_AXI_WR_BUS_SAFETY_ERR_STAT_CMD_INT — Read this bitfield for comparator status for command bus for this port. 1'b1 on any of the bits indicates an error on Command Bus
0x1824C MSS_CTRL_R5SS0_CORE1_AXI_WR_BUS_SAFETY_ERR_STAT ro — This register Indicates the Error Syndrome of Command errors in Bus Safety Comparator of R5SS0 CORE1 AXI WR Initiator Port.
  [28] R5SS0_CORE1_AXI_WR_BUS_SAFETY_ERR_STAT_AXI_B_BRDG — Read this bitfield for comapartor status for axi write response bus from R5SS at this port. 1'b1 on any of the bits indicates an error on Read bus.
  [27] R5SS0_CORE1_AXI_WR_BUS_SAFETY_ERR_STAT_AXI_W_BRDG — Read this bitfield for comparator status for axi write data bus from R5SS for this port. 1'b1 on any of the bits indicates an error on write Bus
  [26] R5SS0_CORE1_AXI_WR_BUS_SAFETY_ERR_STAT_AXI_AW_BRDG — Read this bitfield for comparator status for axi write command bus from R5SS for this port. 1'b1 on any of the bits indicates an error on Command Bus
  [19] R5SS0_CORE1_AXI_WR_BUS_SAFETY_ERR_STAT_VBUSM_WS_BRDG — Read this bitfield for comparator status for vbusm write bus from R5SS for this port. 1'b1 on any of the bits indicates an error on Write Bus
  [18] R5SS0_CORE1_AXI_WR_BUS_SAFETY_ERR_STAT_VBUSM_WR_BRDG — Read this bitfield for comparator status for vbusm write bus from R5SS for this port. 1'b1 on any of the bits indicates an error on Write Bus
  [16] R5SS0_CORE1_AXI_WR_BUS_SAFETY_ERR_STAT_VBUSM_CMD_BRDG — Read this bitfield for comparator status for vbusm command bus from R5SS for this port. 1'b1 on any of the bits indicates an error on Command Bus
  [3] R5SS0_CORE1_AXI_WR_BUS_SAFETY_ERR_STAT_WRITERESP_INT — Read this bitfield for comparator status for Write response bus from interconnect for this port. 1'b1 indicates error on Write Response Bus.
  [2] R5SS0_CORE1_AXI_WR_BUS_SAFETY_ERR_STAT_WRITE_INT — Read this bitfield for comparator status for Write bus from interconnect for this port. 1'b1 at any bit indicates error on Write Bus
  [0] R5SS0_CORE1_AXI_WR_BUS_SAFETY_ERR_STAT_CMD_INT — Read this bitfield for comparator status for command bus for this port. 1'b1 on any of the bits indicates an error on Command Bus
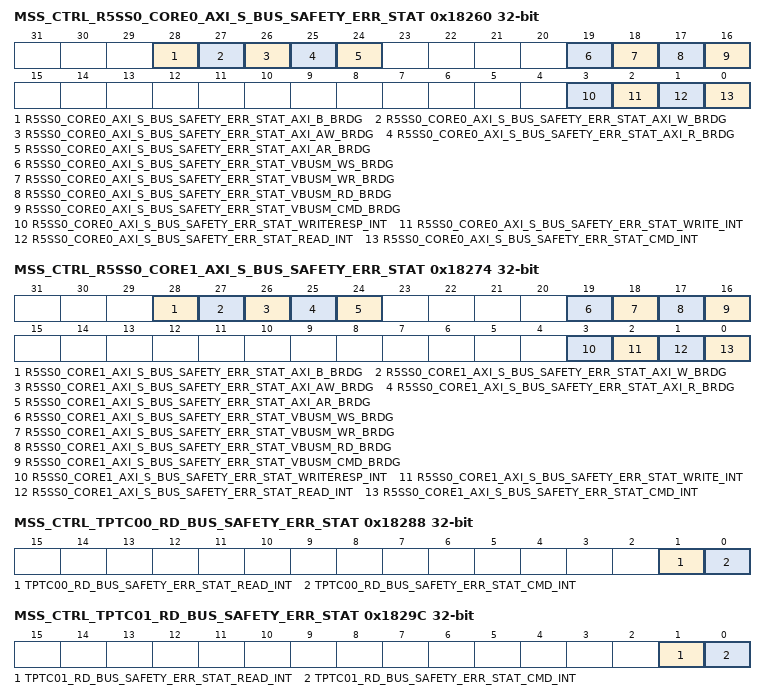
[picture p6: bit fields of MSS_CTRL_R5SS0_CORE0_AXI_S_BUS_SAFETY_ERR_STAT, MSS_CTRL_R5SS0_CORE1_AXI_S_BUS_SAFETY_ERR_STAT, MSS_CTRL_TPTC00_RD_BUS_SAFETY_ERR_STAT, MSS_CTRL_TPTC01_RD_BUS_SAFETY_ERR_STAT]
0x18260 MSS_CTRL_R5SS0_CORE0_AXI_S_BUS_SAFETY_ERR_STAT ro — This register Indicates the Error Syndrome of Command errors in Bus Safety Comparator of R5SS0 CORE0 AXI Target Port.
  [28] R5SS0_CORE0_AXI_S_BUS_SAFETY_ERR_STAT_AXI_B_BRDG — Read this bitfield for comapartor status for axi write response bus from R5SS at this port. 1'b1 on any of the bits indicates an error on Read bus.
  [27] R5SS0_CORE0_AXI_S_BUS_SAFETY_ERR_STAT_AXI_W_BRDG — Read this bitfield for comparator status for axi write data bus from R5SS for this port. 1'b1 on any of the bits indicates an error on write Bus
  [26] R5SS0_CORE0_AXI_S_BUS_SAFETY_ERR_STAT_AXI_AW_BRDG — Read this bitfield for comparator status for axi write command bus from R5SS for this port. 1'b1 on any of the bits indicates an error on Command Bus
  [25] R5SS0_CORE0_AXI_S_BUS_SAFETY_ERR_STAT_AXI_R_BRDG — Read this bitfield for comapartor status for axi read data bus from R5SS at this port. 1'b1 on any of the bits indicates an error on Read bus.
  [24] R5SS0_CORE0_AXI_S_BUS_SAFETY_ERR_STAT_AXI_AR_BRDG — Read this bitfield for comparator status for axi read command bus from R5SS for this port. 1'b1 on any of the bits indicates an error on Command Bus
  [19] R5SS0_CORE0_AXI_S_BUS_SAFETY_ERR_STAT_VBUSM_WS_BRDG — Read this bitfield for comparator status for vbusm write bus from R5SS for this port. 1'b1 on any of the bits indicates an error on Write Bus
  [18] R5SS0_CORE0_AXI_S_BUS_SAFETY_ERR_STAT_VBUSM_WR_BRDG — Read this bitfield for comparator status for vbusm write bus from R5SS for this port. 1'b1 on any of the bits indicates an error on Write Bus
  [17] R5SS0_CORE0_AXI_S_BUS_SAFETY_ERR_STAT_VBUSM_RD_BRDG — Read this bitfield for comapartor status for vbusm read bus from R5SS at this port. 1'b1 on any of the bits indicates an error on Read bus.
  [16] R5SS0_CORE0_AXI_S_BUS_SAFETY_ERR_STAT_VBUSM_CMD_BRDG — Read this bitfield for comparator status for vbusm command bus from R5SS for this port. 1'b1 on any of the bits indicates an error on Command Bus
  [3] R5SS0_CORE0_AXI_S_BUS_SAFETY_ERR_STAT_WRITERESP_INT — Read this bitfield for comparator status for Write response bus from interconnect for this port. 1'b1 indicates error on Write Response Bus.
  [2] R5SS0_CORE0_AXI_S_BUS_SAFETY_ERR_STAT_WRITE_INT — Read this bitfield for comparator status for Write bus from interconnect for this port. 1'b1 at any bit indicates error on Write Bus
  [1] R5SS0_CORE0_AXI_S_BUS_SAFETY_ERR_STAT_READ_INT — Read this bitfield for comapartor status for read signals at this port. 1'b1 on any of the bits indicates an error on Read bus.
  [0] R5SS0_CORE0_AXI_S_BUS_SAFETY_ERR_STAT_CMD_INT — Read this bitfield for comparator status for command bus for this port. 1'b1 on any of the bits indicates an error on Command Bus
0x18274 MSS_CTRL_R5SS0_CORE1_AXI_S_BUS_SAFETY_ERR_STAT ro — This register Indicates the Error Syndrome of Command errors in Bus Safety Comparator of R5SS0 CORE1 AXI Target Port.
  [28] R5SS0_CORE1_AXI_S_BUS_SAFETY_ERR_STAT_AXI_B_BRDG — Read this bitfield for comapartor status for axi write response bus from R5SS at this port. 1'b1 on any of the bits indicates an error on Read bus.
  [27] R5SS0_CORE1_AXI_S_BUS_SAFETY_ERR_STAT_AXI_W_BRDG — Read this bitfield for comparator status for axi write data bus from R5SS for this port. 1'b1 on any of the bits indicates an error on write Bus
  [26] R5SS0_CORE1_AXI_S_BUS_SAFETY_ERR_STAT_AXI_AW_BRDG — Read this bitfield for comparator status for axi write command bus from R5SS for this port. 1'b1 on any of the bits indicates an error on Command Bus
  [25] R5SS0_CORE1_AXI_S_BUS_SAFETY_ERR_STAT_AXI_R_BRDG — Read this bitfield for comapartor status for axi read data bus from R5SS at this port. 1'b1 on any of the bits indicates an error on Read bus.
  [24] R5SS0_CORE1_AXI_S_BUS_SAFETY_ERR_STAT_AXI_AR_BRDG — Read this bitfield for comparator status for axi read command bus from R5SS for this port. 1'b1 on any of the bits indicates an error on Command Bus
  [19] R5SS0_CORE1_AXI_S_BUS_SAFETY_ERR_STAT_VBUSM_WS_BRDG — Read this bitfield for comparator status for vbusm write bus from R5SS for this port. 1'b1 on any of the bits indicates an error on Write Bus
  [18] R5SS0_CORE1_AXI_S_BUS_SAFETY_ERR_STAT_VBUSM_WR_BRDG — Read this bitfield for comparator status for vbusm write bus from R5SS for this port. 1'b1 on any of the bits indicates an error on Write Bus
  [17] R5SS0_CORE1_AXI_S_BUS_SAFETY_ERR_STAT_VBUSM_RD_BRDG — Read this bitfield for comapartor status for vbusm read bus from R5SS at this port. 1'b1 on any of the bits indicates an error on Read bus.
  [16] R5SS0_CORE1_AXI_S_BUS_SAFETY_ERR_STAT_VBUSM_CMD_BRDG — Read this bitfield for comparator status for vbusm command bus from R5SS for this port. 1'b1 on any of the bits indicates an error on Command Bus
  [3] R5SS0_CORE1_AXI_S_BUS_SAFETY_ERR_STAT_WRITERESP_INT — Read this bitfield for comparator status for Write response bus from interconnect for this port. 1'b1 indicates error on Write Response Bus.
  [2] R5SS0_CORE1_AXI_S_BUS_SAFETY_ERR_STAT_WRITE_INT — Read this bitfield for comparator status for Write bus from interconnect for this port. 1'b1 at any bit indicates error on Write Bus
  [1] R5SS0_CORE1_AXI_S_BUS_SAFETY_ERR_STAT_READ_INT — Read this bitfield for comapartor status for read signals at this port. 1'b1 on any of the bits indicates an error on Read bus.
  [0] R5SS0_CORE1_AXI_S_BUS_SAFETY_ERR_STAT_CMD_INT — Read this bitfield for comparator status for command bus for this port. 1'b1 on any of the bits indicates an error on Command Bus
0x18288 MSS_CTRL_TPTC00_RD_BUS_SAFETY_ERR_STAT ro — This register Indicates the Error Syndrome of Command errors in Bus Safety Comparator of TPTC00_RD Initiator Port.
  [1] TPTC00_RD_BUS_SAFETY_ERR_STAT_READ_INT — Read this bitfield for comapartor status for read signals at this port. 1'b1 on any of the bits indicates an error on Read bus.
  [0] TPTC00_RD_BUS_SAFETY_ERR_STAT_CMD_INT — Read this bitfield for comparator status for command bus for this port. 1'b1 on any of the bits indicates an error on Command Bus
0x1829C MSS_CTRL_TPTC01_RD_BUS_SAFETY_ERR_STAT ro — This register Indicates the Error Syndrome of Command errors in Bus Safety Comparator of TPTC01_RD Initiator Port.
  [1] TPTC01_RD_BUS_SAFETY_ERR_STAT_READ_INT — Read this bitfield for comapartor status for read signals at this port. 1'b1 on any of the bits indicates an error on Read bus.
  [0] TPTC01_RD_BUS_SAFETY_ERR_STAT_CMD_INT — Read this bitfield for comparator status for command bus for this port. 1'b1 on any of the bits indicates an error on Command Bus
